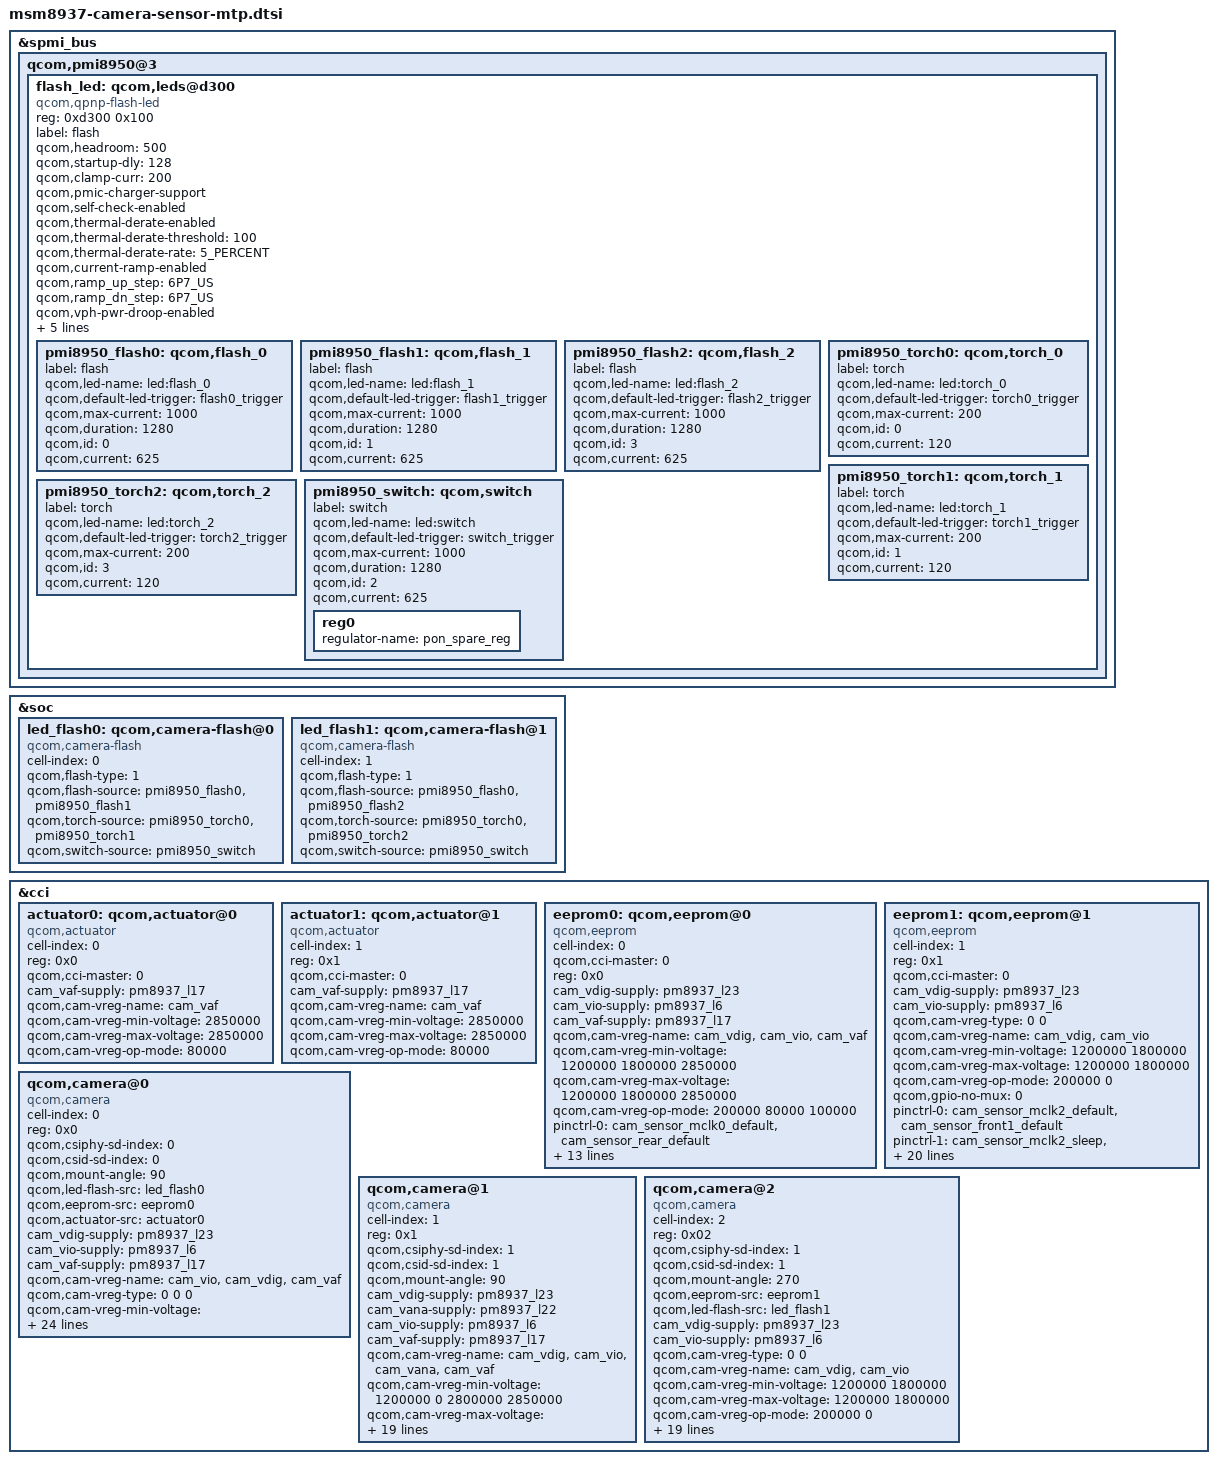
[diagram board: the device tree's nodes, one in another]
/*
 * Copyright (c) 2015-2016, The Linux Foundation. All rights reserved.
 *
 * This program is free software; you can redistribute it and/or modify
 * it under the terms of the GNU General Public License version 2 and
 * only version 2 as published by the Free Software Foundation.
 *
 * This program is distributed in the hope that it will be useful,
 * but WITHOUT ANY WARRANTY; without even the implied warranty of
 * MERCHANTABILITY or FITNESS FOR A PARTICULAR PURPOSE.  See the
 * GNU General Public License for more details.
 */

&spmi_bus {
	qcom,pmi8950@3 {
		flash_led: qcom,leds@d300 {
			compatible = "qcom,qpnp-flash-led";
			status = "okay";
			reg = <0xd300 0x100>;
			label = "flash";
			qcom,headroom = <500>;
			qcom,startup-dly = <128>;
			qcom,clamp-curr = <200>;
			qcom,pmic-charger-support;
			qcom,self-check-enabled;
			qcom,thermal-derate-enabled;
			qcom,thermal-derate-threshold = <100>;
			qcom,thermal-derate-rate = "5_PERCENT";
			qcom,current-ramp-enabled;
			qcom,ramp_up_step = "6P7_US";
			qcom,ramp_dn_step = "6P7_US";
			qcom,vph-pwr-droop-enabled;
			qcom,vph-pwr-droop-threshold = <3000>;
			qcom,vph-pwr-droop-debounce-time = <10>;
			qcom,headroom-sense-ch0-enabled;
			qcom,headroom-sense-ch1-enabled;
			qcom,pmic-revid = <&pmi8950_revid>;

			pmi8950_flash0: qcom,flash_0 {
				label = "flash";
				qcom,led-name = "led:flash_0";
				qcom,default-led-trigger =
						"flash0_trigger";
				qcom,max-current = <1000>;
				qcom,duration = <1280>;
				qcom,id = <0>;
				qcom,current = <625>;
			};

			pmi8950_flash1: qcom,flash_1 {
				label = "flash";
				qcom,led-name = "led:flash_1";
				qcom,default-led-trigger =
						"flash1_trigger";
				qcom,max-current = <1000>;
				qcom,duration = <1280>;
				qcom,id = <1>;
				qcom,current = <625>;
			};

			pmi8950_flash2: qcom,flash_2 {
				label = "flash";
				qcom,led-name = "led:flash_2";
				qcom,default-led-trigger =
						"flash2_trigger";
				qcom,max-current = <1000>;
				qcom,duration = <1280>;
				qcom,id = <3>;
				qcom,current = <625>;
			};

			pmi8950_torch0: qcom,torch_0 {
				label = "torch";
				qcom,led-name = "led:torch_0";
				qcom,default-led-trigger =
						"torch0_trigger";
				qcom,max-current = <200>;
				qcom,id = <0>;
				qcom,current = <120>;
			};

			pmi8950_torch1: qcom,torch_1 {
				label = "torch";
				qcom,led-name = "led:torch_1";
				qcom,default-led-trigger =
						"torch1_trigger";
				qcom,max-current = <200>;
				qcom,id = <1>;
				qcom,current = <120>;
			};

			pmi8950_torch2: qcom,torch_2 {
				label = "torch";
				qcom,led-name = "led:torch_2";
				qcom,default-led-trigger =
						"torch2_trigger";
				qcom,max-current = <200>;
				qcom,id = <3>;
				qcom,current = <120>;

			};

			pmi8950_switch: qcom,switch {
				label = "switch";
				qcom,led-name = "led:switch";
				qcom,default-led-trigger =
						"switch_trigger";
				qcom,max-current = <1000>;
				qcom,duration = <1280>;
				qcom,id = <2>;
				qcom,current = <625>;
                                //when LCD turn off,flashlight blinking.wupingzhou,20160625
				reg0 {
					regulator-name = "pon_spare_reg";
				};
			};
		};
	};
};

&soc {
	led_flash0: qcom,camera-flash@0 {
		cell-index = <0>;
		compatible = "qcom,camera-flash";
		qcom,flash-type = <1>;
		qcom,flash-source = <&pmi8950_flash0 &pmi8950_flash1>;
		qcom,torch-source = <&pmi8950_torch0 &pmi8950_torch1>;
		qcom,switch-source = <&pmi8950_switch>;
	};

	led_flash1: qcom,camera-flash@1 {
		cell-index = <1>;
		compatible = "qcom,camera-flash";
		qcom,flash-type = <1>;
		qcom,flash-source = <&pmi8950_flash0 &pmi8950_flash2>;
		qcom,torch-source = <&pmi8950_torch0 &pmi8950_torch2>;
		qcom,switch-source = <&pmi8950_switch>;
	};
};

&cci {
	actuator0: qcom,actuator@0 {
		cell-index = <0>;
		reg = <0x0>;
		compatible = "qcom,actuator";
		qcom,cci-master = <0>;
		cam_vaf-supply = <&pm8937_l17>;
		qcom,cam-vreg-name = "cam_vaf";
		qcom,cam-vreg-min-voltage = <2850000>;
		qcom,cam-vreg-max-voltage = <2850000>;
		qcom,cam-vreg-op-mode = <80000>;
	};

	actuator1: qcom,actuator@1 {
		cell-index = <1>;
		reg = <0x1>;
		compatible = "qcom,actuator";
		qcom,cci-master = <0>;
		cam_vaf-supply = <&pm8937_l17>;
		qcom,cam-vreg-name = "cam_vaf";
		qcom,cam-vreg-min-voltage = <2850000>;
		qcom,cam-vreg-max-voltage = <2850000>;
		qcom,cam-vreg-op-mode = <80000>;
	};

	eeprom0: qcom,eeprom@0 {
		cell-index = <0>;
		compatible = "qcom,eeprom";
		qcom,cci-master = <0>;
		reg = <0x0>;
		cam_vdig-supply = <&pm8937_l23>;

		cam_vio-supply = <&pm8937_l6>;
		cam_vaf-supply = <&pm8937_l17>;
		qcom,cam-vreg-name = "cam_vdig", "cam_vio","cam_vaf";
		qcom,cam-vreg-min-voltage = <1200000  1800000 2850000>;
		qcom,cam-vreg-max-voltage = <1200000  1800000 2850000>;
		qcom,cam-vreg-op-mode = <200000  80000 100000>;
		pinctrl-names = "cam_default", "cam_suspend";
		pinctrl-0 = <&cam_sensor_mclk0_default
				&cam_sensor_rear_default>;
		pinctrl-1 = <&cam_sensor_mclk0_sleep &cam_sensor_rear_sleep>;
		gpios = <&tlmm 26 0>,
			<&tlmm 36 0>,
			<&tlmm 35 0>,
			<&tlmm 125 0>;
		qcom,gpio-reset = <1>;
		qcom,gpio-standby = <2>;
		qcom,gpio-vana = <3>;
		qcom,gpio-req-tbl-num = <0 1 2 3>;
		qcom,gpio-req-tbl-flags = <1 0 0 0>;
		qcom,gpio-req-tbl-label = "CAMIF_MCLK0",
			"CAM_RESET0",
			"CAM_STANDBY0",
			"CAM_VANA";
		status = "ok";
		clocks = <&clock_gcc clk_mclk0_clk_src>,
				<&clock_gcc clk_gcc_camss_mclk0_clk>;
		clock-names = "cam_src_clk", "cam_clk";
		qcom,clock-rates = <19200000 0>;
	};

	eeprom1: qcom,eeprom@1 {
		cell-index = <1>;
		reg = <0x1>;

		compatible = "qcom,eeprom";

		qcom,cci-master = <0>;



		cam_vdig-supply = <&pm8937_l23>;

		cam_vio-supply = <&pm8937_l6>;

        	qcom,cam-vreg-type = <0 0>;
		qcom,cam-vreg-name = "cam_vdig", "cam_vio";
		qcom,cam-vreg-min-voltage = <1200000 1800000>;
		qcom,cam-vreg-max-voltage = <1200000 1800000>;
		qcom,cam-vreg-op-mode = <200000 0>;

		qcom,gpio-no-mux = <0>;
		pinctrl-names = "cam_default", "cam_suspend";
		pinctrl-0 = <&cam_sensor_mclk2_default
			&cam_sensor_front1_default>;
		pinctrl-1 = <&cam_sensor_mclk2_sleep &cam_sensor_front1_sleep>;
		gpios = <&tlmm 28 0>,
			<&tlmm 40 0>,
			<&tlmm 39 0>,
			<&tlmm 125 0>;

		qcom,gpio-reset = <1>;
		qcom,gpio-standby = <2>;
		qcom,gpio-vana = <3>;
		qcom,gpio-req-tbl-num = <0 1 2 3>;
		qcom,gpio-req-tbl-flags = <1 0 0 0>;
		qcom,gpio-req-tbl-label = "CAMIF_MCLK2",
					  "CAM_RESET2",
					  "CAM_STANDBY2",
					  "CAM_VANA";

		qcom,cam-power-seq-type = "sensor_vreg","sensor_vreg",
			"sensor_gpio", "sensor_gpio", "sensor_gpio" , "sensor_clk";
		qcom,cam-power-seq-val = "cam_vdig", "cam_vio",
			"sensor_gpio_reset", "sensor_gpio_standby","sensor_gpio_vana",
			"sensor_cam_mclk";
		qcom,cam-power-seq-cfg-val = <1 1 1 1 1 24000000>;
		qcom,cam-power-seq-delay = <1 1 30 30 30 5>;
		status = "ok";
		clocks = <&clock_gcc clk_mclk2_clk_src>,
			<&clock_gcc clk_gcc_camss_mclk2_clk>;
		clock-names = "cam_src_clk", "cam_clk";
		qcom,clock-rates = <19200000 0>;
	};

	qcom,camera@0 {
		cell-index = <0>;
		compatible = "qcom,camera";
		reg = <0x0>;
		qcom,csiphy-sd-index = <0>;
		qcom,csid-sd-index = <0>;
		qcom,mount-angle = <90>;
		qcom,led-flash-src = <&led_flash0>;
		qcom,eeprom-src = <&eeprom0>;
		qcom,actuator-src = <&actuator0>;
		cam_vdig-supply = <&pm8937_l23>;

		cam_vio-supply = <&pm8937_l6>;
		cam_vaf-supply = <&pm8937_l17>;

		qcom,cam-vreg-name = "cam_vio","cam_vdig",
    							"cam_vaf";
		qcom,cam-vreg-type = <0 0 0>;

		qcom,cam-vreg-min-voltage = <1800000 1200000 2850000>;
		qcom,cam-vreg-max-voltage = <1800000 2800000 2950000>;
		qcom,cam-vreg-op-mode = <0 80000 100000>;
		pinctrl-names = "cam_default", "cam_suspend";
		pinctrl-0 = <&cam_sensor_mclk0_default
				&cam_sensor_rear_default
				&cam_sensor_rear_vana>;
		pinctrl-1 = <&cam_sensor_mclk0_sleep &cam_sensor_rear_sleep
				&cam_sensor_rear_vana_sleep>;
		gpios = <&tlmm 26 0>,
			<&tlmm 36 0>,
			<&tlmm 35 0>,
			<&tlmm 125 0>;

		qcom,gpio-reset = <1>;
		qcom,gpio-standby = <2>;
		qcom,gpio-vana = <3>;

		qcom,gpio-req-tbl-num = <0 1 2 3 >;
		qcom,gpio-req-tbl-flags = <1 0 0 0>;
		qcom,gpio-req-tbl-label = "CAMIF_MCLK0",
			"CAM_RESET0",
			"CAM_STANDBY0",
			"CAM_VANA";

		qcom,sensor-position = <0>;
		qcom,sensor-mode = <0>;
		qcom,cci-master = <0>;
		status = "ok";
		clocks = <&clock_gcc clk_mclk0_clk_src>,
				<&clock_gcc clk_gcc_camss_mclk0_clk>;
		clock-names = "cam_src_clk", "cam_clk";
		qcom,clock-rates = <24000000 0>;
	};

	qcom,camera@1 {
		cell-index = <1>;
		compatible = "qcom,camera";
		reg = <0x1>;
		qcom,csiphy-sd-index = <1>;
		qcom,csid-sd-index = <1>;
		qcom,mount-angle = <90>;
		cam_vdig-supply = <&pm8937_l23>;
		cam_vana-supply = <&pm8937_l22>;
		cam_vio-supply = <&pm8937_l6>;
		cam_vaf-supply = <&pm8937_l17>;
		qcom,cam-vreg-name = "cam_vdig", "cam_vio", "cam_vana",
							"cam_vaf";
		qcom,cam-vreg-min-voltage = <1200000 0 2800000 2850000>;
		qcom,cam-vreg-max-voltage = <1200000 0 2800000 2850000>;
		qcom,cam-vreg-op-mode = <200000 0 80000 100000>;
		pinctrl-names = "cam_default", "cam_suspend";
		pinctrl-0 = <&cam_sensor_mclk1_default
				&cam_sensor_front_default>;
		pinctrl-1 = <&cam_sensor_mclk1_sleep
				&cam_sensor_front_sleep>;
		gpios = <&tlmm 27 0>,
			<&tlmm 38 0>,
			<&tlmm 50 0>;
		qcom,gpio-reset = <1>;
		qcom,gpio-standby = <2>;
		qcom,gpio-req-tbl-num = <0 1 2>;
		qcom,gpio-req-tbl-flags = <1 0 0>;
		qcom,gpio-req-tbl-label = "CAMIF_MCLK1",
			"CAM_RESET1",
			"CAM_STANDBY1";
		qcom,sensor-position = <0x100>;
		qcom,sensor-mode = <1>;
		qcom,cci-master = <1>;
		clocks = <&clock_gcc clk_mclk1_clk_src>,
				<&clock_gcc clk_gcc_camss_mclk1_clk>;
		clock-names = "cam_src_clk", "cam_clk";
		qcom,clock-rates = <24000000 0>;
	};

	qcom,camera@2 {
		cell-index = <2>;
		compatible = "qcom,camera";
		reg = <0x02>;
		qcom,csiphy-sd-index = <1>;
		qcom,csid-sd-index = <1>;
		qcom,mount-angle = <270>;
		qcom,eeprom-src = <&eeprom1>;
		qcom,led-flash-src = <&led_flash1>;
                cam_vdig-supply = <&pm8937_l23>;
		cam_vio-supply = <&pm8937_l6>;
		qcom,cam-vreg-type = <0 0>;
		qcom,cam-vreg-name = "cam_vdig", "cam_vio";
		qcom,cam-vreg-min-voltage = <1200000 1800000>;
		qcom,cam-vreg-max-voltage = <1200000 1800000>;
		qcom,cam-vreg-op-mode = <200000 0>;
		qcom,gpio-no-mux = <0>;
		pinctrl-names = "cam_default", "cam_suspend";
		pinctrl-0 = <&cam_sensor_mclk2_default
				&cam_sensor_front1_default>;
		pinctrl-1 = <&cam_sensor_mclk2_sleep
				&cam_sensor_front1_sleep>;
		gpios = <&tlmm 28 0>,
			<&tlmm 40 0>,
			<&tlmm 39 0>,
			<&tlmm 125 0>;
		qcom,gpio-reset = <1>;
		qcom,gpio-standby = <2>;
		qcom,gpio-vana = <3>;
		qcom,gpio-req-tbl-num = <0 1 2 3>;
		qcom,gpio-req-tbl-flags = <1 0 0 0>;
		qcom,gpio-req-tbl-label = "CAMIF_MCLK2",
					  "CAM_RESET2",
					  "CAM_STANDBY2",
					  "CAM_VANA";
		qcom,sensor-position = <1>;
		qcom,sensor-mode = <0>;
		qcom,cci-master = <0>;
		status = "ok";
		clocks = <&clock_gcc clk_mclk2_clk_src>,
			<&clock_gcc clk_gcc_camss_mclk2_clk>;
		clock-names = "cam_src_clk", "cam_clk";
		qcom,clock-rates = <24000000 0>;
	};
};
